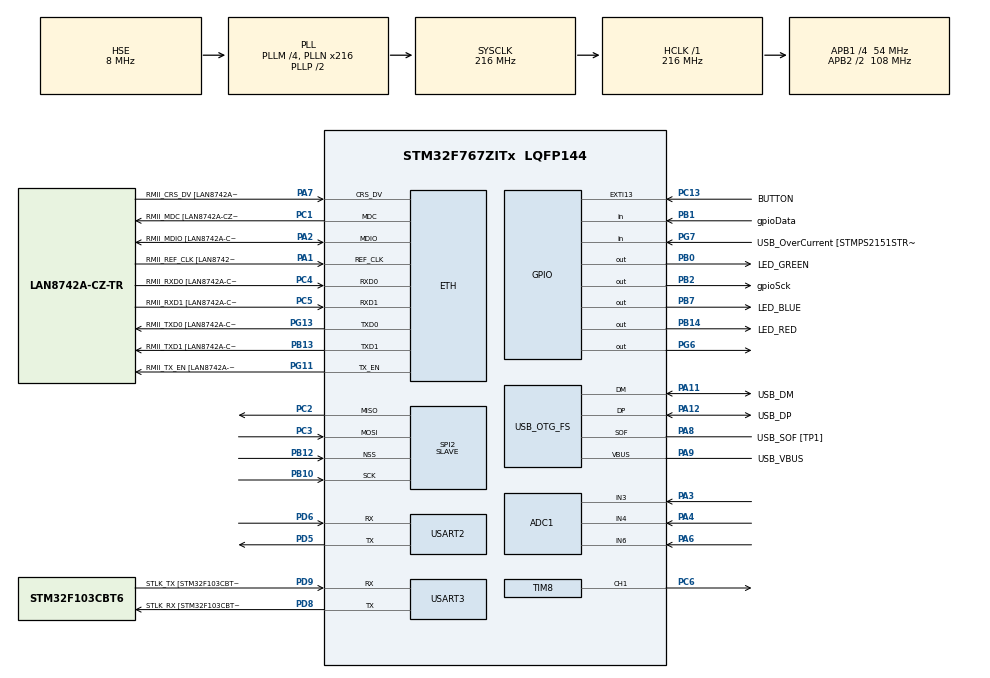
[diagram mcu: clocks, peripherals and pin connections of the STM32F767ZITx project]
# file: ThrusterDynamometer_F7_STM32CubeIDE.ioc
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ADC1.Channel-0\#ChannelRegularConversion=ADC_CHANNEL_3
ADC1.Channel-1\#ChannelRegularConversion=ADC_CHANNEL_4
ADC1.Channel-2\#ChannelRegularConversion=ADC_CHANNEL_6
ADC1.ClockPrescaler=ADC_CLOCK_SYNC_PCLK_DIV8
ADC1.DMAContinuousRequests=ENABLE
ADC1.ExternalTrigConv=ADC_EXTERNALTRIGCONV_T2_TRGO
ADC1.NbrOfConversion=3
ADC1.NbrOfConversionFlag=1
ADC1.Rank-0\#ChannelRegularConversion=1
ADC1.Rank-1\#ChannelRegularConversion=2
ADC1.Rank-2\#ChannelRegularConversion=3
ADC1.SamplingTime-0\#ChannelRegularConversion=ADC_SAMPLETIME_480CYCLES
ADC1.SamplingTime-1\#ChannelRegularConversion=ADC_SAMPLETIME_480CYCLES
ADC1.SamplingTime-2\#ChannelRegularConversion=ADC_SAMPLETIME_480CYCLES
ADC1.ScanConvMode=ADC_SCAN_ENABLE
ADC1.master=1
Dma.ADC1.1.Direction=DMA_PERIPH_TO_MEMORY
Dma.ADC1.1.FIFOMode=DMA_FIFOMODE_DISABLE
Dma.ADC1.1.Instance=DMA2_Stream0
Dma.ADC1.1.MemDataAlignment=DMA_MDATAALIGN_WORD
Dma.ADC1.1.MemInc=DMA_MINC_ENABLE
Dma.ADC1.1.Mode=DMA_CIRCULAR
Dma.ADC1.1.PeriphDataAlignment=DMA_PDATAALIGN_WORD
Dma.ADC1.1.PeriphInc=DMA_PINC_DISABLE
Dma.ADC1.1.Priority=DMA_PRIORITY_LOW
Dma.Request0=USART2_RX
Dma.Request1=ADC1
Dma.Request2=TIM8_CH1
Dma.Request3=SPI2_RX
Dma.Request4=SPI2_TX
Dma.SPI2_RX.3.Direction=DMA_PERIPH_TO_MEMORY
Dma.SPI2_RX.3.FIFOMode=DMA_FIFOMODE_ENABLE
Dma.SPI2_RX.3.FIFOThreshold=DMA_FIFO_THRESHOLD_FULL
Dma.SPI2_RX.3.Instance=DMA1_Stream1
Dma.SPI2_RX.3.MemBurst=DMA_MBURST_SINGLE
Dma.SPI2_RX.3.MemDataAlignment=DMA_MDATAALIGN_BYTE
Dma.SPI2_RX.3.MemInc=DMA_MINC_ENABLE
Dma.SPI2_RX.3.Mode=DMA_NORMAL
Dma.SPI2_RX.3.PeriphBurst=DMA_PBURST_SINGLE
Dma.SPI2_RX.3.PeriphDataAlignment=DMA_PDATAALIGN_BYTE
Dma.SPI2_RX.3.PeriphInc=DMA_PINC_DISABLE
Dma.SPI2_RX.3.Priority=DMA_PRIORITY_LOW
Dma.SPI2_TX.4.Direction=DMA_MEMORY_TO_PERIPH
Dma.SPI2_TX.4.FIFOMode=DMA_FIFOMODE_ENABLE
Dma.SPI2_TX.4.FIFOThreshold=DMA_FIFO_THRESHOLD_FULL
Dma.SPI2_TX.4.Instance=DMA1_Stream4
Dma.SPI2_TX.4.MemBurst=DMA_MBURST_SINGLE
Dma.SPI2_TX.4.MemDataAlignment=DMA_MDATAALIGN_BYTE
Dma.SPI2_TX.4.MemInc=DMA_MINC_ENABLE
Dma.SPI2_TX.4.Mode=DMA_NORMAL
Dma.SPI2_TX.4.PeriphBurst=DMA_PBURST_SINGLE
Dma.SPI2_TX.4.PeriphDataAlignment=DMA_PDATAALIGN_BYTE
Dma.SPI2_TX.4.PeriphInc=DMA_PINC_DISABLE
Dma.SPI2_TX.4.Priority=DMA_PRIORITY_LOW
Dma.TIM8_CH1.2.Direction=DMA_PERIPH_TO_MEMORY
Dma.TIM8_CH1.2.FIFOMode=DMA_FIFOMODE_DISABLE
Dma.TIM8_CH1.2.Instance=DMA2_Stream2
Dma.TIM8_CH1.2.MemDataAlignment=DMA_MDATAALIGN_HALFWORD
Dma.TIM8_CH1.2.MemInc=DMA_MINC_ENABLE
Dma.TIM8_CH1.2.Mode=DMA_CIRCULAR
Dma.TIM8_CH1.2.PeriphDataAlignment=DMA_PDATAALIGN_HALFWORD
Dma.TIM8_CH1.2.PeriphInc=DMA_PINC_DISABLE
Dma.TIM8_CH1.2.Priority=DMA_PRIORITY_LOW
Dma.USART2_RX.0.Direction=DMA_PERIPH_TO_MEMORY
Dma.USART2_RX.0.FIFOMode=DMA_FIFOMODE_DISABLE
Dma.USART2_RX.0.Instance=DMA1_Stream5
Dma.USART2_RX.0.MemDataAlignment=DMA_MDATAALIGN_BYTE
Dma.USART2_RX.0.MemInc=DMA_MINC_ENABLE
Dma.USART2_RX.0.Mode=DMA_NORMAL
Dma.USART2_RX.0.PeriphDataAlignment=DMA_PDATAALIGN_BYTE
Dma.USART2_RX.0.PeriphInc=DMA_PINC_DISABLE
Dma.USART2_RX.0.Priority=DMA_PRIORITY_LOW
ETH.MediaInterface=ETH_MEDIA_INTERFACE_RMII
ETH.PHY_Name=LAN8742A_PHY_ADDRESS
ETH.PHY_Value=0
ETH.PhyAddress=0
FREERTOS.Tasks01=defaultTask,0,128,StartDefaultTask,Default,NULL,Dynamic,NULL,NULL
FREERTOS.configTOTAL_HEAP_SIZE=50000
FREERTOS.configUSE_TIMERS=1
LWIP.IP_ADDRESS=169.254.000.055
LWIP.LWIP_DHCP=0
LWIP.NETMASK_ADDRESS=255.255.000.000
LWIP.Version=v2.1.2_Cube
Mcu.Family=STM32F7
Mcu.Name=STM32F767ZITx
Mcu.Package=LQFP144
NVIC.DMA1_Stream1_IRQn=true\:5\:0\:false\:false\:true\:true\:false\:true
NVIC.DMA1_Stream4_IRQn=true\:5\:0\:false\:false\:true\:true\:false\:true
NVIC.DMA1_Stream5_IRQn=true\:5\:0\:false\:false\:true\:true\:false\:true
NVIC.DMA2_Stream0_IRQn=true\:5\:0\:false\:false\:true\:true\:false\:true
NVIC.DMA2_Stream2_IRQn=true\:5\:0\:false\:false\:true\:true\:false\:true
NVIC.ETH_IRQn=true\:5\:0\:false\:false\:true\:true\:false\:true
NVIC.PriorityGroup=NVIC_PRIORITYGROUP_4
NVIC.SPI2_IRQn=true\:5\:0\:false\:false\:true\:true\:true\:true
NVIC.TIM1_BRK_TIM9_IRQn=true\:5\:0\:false\:false\:true\:true\:true\:true
NVIC.TIM1_TRG_COM_TIM11_IRQn=true\:5\:0\:false\:false\:true\:true\:true\:true
NVIC.TIM1_UP_TIM10_IRQn=true\:0\:0\:false\:false\:true\:false\:false\:true
NVIC.TIM2_IRQn=true\:5\:0\:false\:false\:true\:true\:true\:true
NVIC.TimeBase=TIM1_UP_TIM10_IRQn
NVIC.TimeBaseIP=TIM1
NVIC.USART2_IRQn=true\:5\:0\:false\:false\:true\:true\:true\:true
NVIC.USART3_IRQn=true\:5\:0\:false\:false\:true\:true\:true\:true
PA1.GPIO_Label=RMII_REF_CLK [LAN8742A-CZ-TR_REFCLK0]
PA1.Mode=RMII
PA1.Signal=ETH_REF_CLK
PA10.GPIO_Label=USB_ID
PA10.Signal=USB_OTG_FS_ID
PA11.GPIO_Label=USB_DM
PA11.Mode=Device_Only
PA11.Signal=USB_OTG_FS_DM
PA12.GPIO_Label=USB_DP
PA12.Mode=Device_Only
PA12.Signal=USB_OTG_FS_DP
PA13.GPIO_Label=TMS
PA13.Mode=Serial_Wire
PA13.Signal=SYS_JTMS-SWDIO
PA14.GPIO_Label=TCK
PA14.Mode=Serial_Wire
PA14.Signal=SYS_JTCK-SWCLK
PA2.GPIO_Label=RMII_MDIO [LAN8742A-CZ-TR_MDIO]
PA2.Mode=RMII
PA2.Signal=ETH_MDIO
PA3.Signal=ADCx_IN3
PA4.Signal=ADCx_IN4
PA6.Signal=ADCx_IN6
PA7.GPIO_Label=RMII_CRS_DV [LAN8742A-CZ-TR_CRS_DV]
PA7.Mode=RMII
PA7.Signal=ETH_CRS_DV
PA8.GPIO_Label=USB_SOF [TP1]
PA8.Mode=Activate_SOF_FS
PA8.Signal=USB_OTG_FS_SOF
PA9.GPIO_Label=USB_VBUS
PA9.Mode=Activate_VBUS
PA9.Signal=USB_OTG_FS_VBUS
PB0.GPIO_Label=LED_GREEN
PB0.Signal=GPIO_Output
PB1.GPIO_Label=gpioData
PB1.Signal=GPIO_Input
PB10.Mode=Full_Duplex_Slave
PB10.Signal=SPI2_SCK
PB12.Mode=NSS_Signal_Hard_Input
PB12.Signal=SPI2_NSS
PB13.GPIO_Label=RMII_TXD1 [LAN8742A-CZ-TR_TXD1]
PB13.Mode=RMII
PB13.Signal=ETH_TXD1
PB14.GPIO_Label=LED_RED
PB14.Signal=GPIO_Output
PB2.GPIO_Label=gpioSck
PB2.Signal=GPIO_Output
PB3.GPIO_Label=SWO
PB3.Signal=SYS_JTDO-SWO
PB7.GPIO_Label=LED_BLUE
PB7.Signal=GPIO_Output
PC1.GPIO_Label=RMII_MDC [LAN8742A-CZ-TR_MDC]
PC1.Mode=RMII
PC1.Signal=ETH_MDC
PC13.GPIO_Label=BUTTON
PC13.Signal=GPXTI13
PC14/OSC32_IN.Mode=LSE-External-Oscillator
PC14/OSC32_IN.Signal=RCC_OSC32_IN
PC15/OSC32_OUT.Mode=LSE-External-Oscillator
PC15/OSC32_OUT.Signal=RCC_OSC32_OUT
PC2.Mode=Full_Duplex_Slave
PC2.Signal=SPI2_MISO
PC3.Mode=Full_Duplex_Slave
PC3.Signal=SPI2_MOSI
PC4.GPIO_Label=RMII_RXD0 [LAN8742A-CZ-TR_RXD0]
PC4.Mode=RMII
PC4.Signal=ETH_RXD0
PC5.GPIO_Label=RMII_RXD1 [LAN8742A-CZ-TR_RXD1]
PC5.Mode=RMII
PC5.Signal=ETH_RXD1
PC6.Signal=S_TIM8_CH1
PD5.Mode=Asynchronous
PD5.Signal=USART2_TX
PD6.Mode=Asynchronous
PD6.Signal=USART2_RX
PD8.GPIO_Label=STLK_RX [STM32F103CBT6_PA3]
PD8.Mode=Asynchronous
PD8.Signal=USART3_TX
PD9.GPIO_Label=STLK_TX [STM32F103CBT6_PA2]
PD9.Mode=Asynchronous
PD9.Signal=USART3_RX
PG11.GPIO_Label=RMII_TX_EN [LAN8742A-CZ-TR_TXEN]
PG11.Mode=RMII
PG11.Signal=ETH_TX_EN
PG13.GPIO_Label=RMII_TXD0 [LAN8742A-CZ-TR_TXD0]
PG13.Mode=RMII
PG13.Signal=ETH_TXD0
PG6.Signal=GPIO_Output
PG7.GPIO_Label=USB_OverCurrent [STMPS2151STR_FAULT]
PG7.Signal=GPIO_Input
PH0/OSC_IN.GPIO_Label=MCO [STM32F103CBT6_PA8]
PH0/OSC_IN.Mode=HSE-External-Clock-Source
PH0/OSC_IN.Signal=RCC_OSC_IN
PH1/OSC_OUT.Mode=HSE-External-Clock-Source
PH1/OSC_OUT.Signal=RCC_OSC_OUT
ProjectManager.HeapSize=0x200
ProjectManager.StackSize=0x400
ProjectManager.TargetToolchain=STM32CubeIDE
RCC.48MHZClocksFreq_Value=24000000
RCC.AHBFreq_Value=216000000
RCC.APB1CLKDivider=RCC_HCLK_DIV4
RCC.APB1Freq_Value=54000000
RCC.APB1TimFreq_Value=108000000
RCC.APB2CLKDivider=RCC_HCLK_DIV2
RCC.APB2Freq_Value=108000000
RCC.APB2TimFreq_Value=216000000
RCC.CortexFreq_Value=216000000
RCC.HCLKFreq_Value=216000000
RCC.HSE_VALUE=8000000
RCC.HSI_VALUE=16000000
RCC.PLLM=4
RCC.PLLMUL=RCC_PLL_MUL9
RCC.PLLN=216
RCC.PLLQ=9
RCC.PRESCALERUSB=RCC_USBCLKSOURCE_PLL_DIV1_5
RCC.SYSCLKFreq_VALUE=216000000
RCC.SYSCLKSource=RCC_SYSCLKSOURCE_PLLCLK
RCC.SYSCLKSourceVirtual=RCC_SYSCLKSOURCE_PLLCLK
RCC.USBFreq_Value=48000000
RCC.VCOOutputFreq_Value=432000000
SH.ADCx_IN3.0=ADC1_IN3,IN3
SH.ADCx_IN4.0=ADC1_IN4,IN4
SH.ADCx_IN6.0=ADC1_IN6,IN6
SH.S_TIM8_CH1.0=TIM8_CH1,PWM Generation1 CH1
SPI2.DataSize=SPI_DATASIZE_8BIT
SPI2.Direction=SPI_DIRECTION_2LINES
SPI2.Mode=SPI_MODE_SLAVE
SPI2.VirtualNSS=VM_NSSHARD
SPI2.VirtualType=VM_SLAVE
TIM11.Period=999
TIM11.Prescaler=2159
TIM2.Period=999
TIM2.Prescaler=1079
TIM2.TIM_MasterOutputTrigger=TIM_TRGO_UPDATE
TIM8.Channel-PWM\ Generation1\ CH1=TIM_CHANNEL_1
TIM8.Period=10000
TIM8.Prescaler=440
TIM9.Period=9999
TIM9.Prescaler=2159
USART2.VirtualMode-Asynchronous=VM_ASYNC
USART3.VirtualMode-Asynchronous=VM_ASYNC
USB_OTG_FS.VirtualMode=Device_Only
VP_FREERTOS_VS_CMSIS_V1.Mode=CMSIS_V1
VP_LWIP_VS_Enabled.Mode=Enabled
VP_SYS_VS_tim1.Mode=TIM1
VP_TIM11_VS_ClockSourceINT.Mode=Enable_Timer
VP_TIM2_VS_ClockSourceINT.Mode=Internal
VP_TIM9_VS_ClockSourceINT.Mode=Internal
board=NUCLEO-F767ZI

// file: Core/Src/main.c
/* USER CODE BEGIN Header */
/**
  ******************************************************************************
  * @file           : main.c
  * @brief          : Main program body
  ******************************************************************************
  * @attention
  *
  * <h2><center>&copy; Copyright (c) 2020 STMicroelectronics.
  * All rights reserved.</center></h2>
  *
  * This software component is licensed by ST under Ultimate Liberty license
  * SLA0044, the "License"; You may not use this file except in compliance with
  * the License. You may obtain a copy of the License at:
  *                             www.st.com/SLA0044
  *
  ******************************************************************************
  */
/* USER CODE END Header */

#include "main.h"
#include "cmsis_os.h"
#include "lwip.h"
#include "thruster_control_module.h"

ADC_HandleTypeDef hadc1;
DMA_HandleTypeDef hdma_adc1;

SPI_HandleTypeDef hspi2;
DMA_HandleTypeDef hdma_spi2_rx;
DMA_HandleTypeDef hdma_spi2_tx;

TIM_HandleTypeDef htim2;
TIM_HandleTypeDef htim8;
TIM_HandleTypeDef htim9;
TIM_HandleTypeDef htim11;
DMA_HandleTypeDef hdma_tim8_ch1;

UART_HandleTypeDef huart2;
UART_HandleTypeDef huart3;
DMA_HandleTypeDef hdma_usart2_rx;

PCD_HandleTypeDef hpcd_USB_OTG_FS;

osThreadId defaultTaskHandle;

void SystemClock_Config(void);
static void MX_GPIO_Init(void);
static void MX_DMA_Init(void);
static void MX_USART3_UART_Init(void);
static void MX_USB_OTG_FS_PCD_Init(void);
static void MX_ADC1_Init(void);
static void MX_TIM2_Init(void);
static void MX_TIM8_Init(void);
static void MX_TIM9_Init(void);
static void MX_TIM11_Init(void);
static void MX_USART2_UART_Init(void);
static void MX_SPI2_Init(void);
void StartDefaultTask(void const * argument);

/* USER CODE BEGIN 0 */

#define UART_DATA_LEN	100
uint8_t data[UART_DATA_LEN];

/* USER CODE END 0 */

int main(void)
{

  /* MCU Configuration--------------------------------------------------------*/

  /* Reset of all peripherals, Initializes the Flash interface and the Systick. */
  HAL_Init();

  /* Configure the system clock */
  SystemClock_Config();

  /* Initialize all configured peripherals */
  MX_GPIO_Init();
  MX_DMA_Init();
  MX_USART3_UART_Init();
  MX_USB_OTG_FS_PCD_Init();
  MX_ADC1_Init();
  MX_TIM2_Init();
  MX_TIM8_Init();
  MX_TIM9_Init();
  MX_TIM11_Init();
  MX_USART2_UART_Init();
  MX_SPI2_Init();

  /* Create the thread(s) */
  /* definition and creation of defaultTask */
//  osThreadDef(defaultTask, StartDefaultTask, osPriorityNormal, 0, 128);
//  defaultTaskHandle = osThreadCreate(osThread(defaultTask), NULL);

  ThrusterControlModule_InitSystem();

  /* Start scheduler */
  osKernelStart();

  /* We should never get here as control is now taken by the scheduler */
  /* Infinite loop */
  while (1)
  {

  }
}

void SystemClock_Config(void)
{
  RCC_OscInitTypeDef RCC_OscInitStruct = {0};
  RCC_ClkInitTypeDef RCC_ClkInitStruct = {0};
  RCC_PeriphCLKInitTypeDef PeriphClkInitStruct = {0};

  /** Configure LSE Drive Capability
  */
  HAL_PWR_EnableBkUpAccess();
  /** Configure the main internal regulator output voltage
  */
  __HAL_RCC_PWR_CLK_ENABLE();
  __HAL_PWR_VOLTAGESCALING_CONFIG(PWR_REGULATOR_VOLTAGE_SCALE1);
  /** Initializes the CPU, AHB and APB busses clocks
  */
  RCC_OscInitStruct.OscillatorType = RCC_OSCILLATORTYPE_HSE;
  RCC_OscInitStruct.HSEState = RCC_HSE_BYPASS;
  RCC_OscInitStruct.PLL.PLLState = RCC_PLL_ON;
  RCC_OscInitStruct.PLL.PLLSource = RCC_PLLSOURCE_HSE;
  RCC_OscInitStruct.PLL.PLLM = 4;
  RCC_OscInitStruct.PLL.PLLN = 216;
  RCC_OscInitStruct.PLL.PLLP = RCC_PLLP_DIV2;
  RCC_OscInitStruct.PLL.PLLQ = 9;
  if (HAL_RCC_OscConfig(&RCC_OscInitStruct) != HAL_OK)
  {
    Error_Handler();
  }
  /** Activate the Over-Drive mode
  */
  if (HAL_PWREx_EnableOverDrive() != HAL_OK)
  {
    Error_Handler();
  }
  /** Initializes the CPU, AHB and APB busses clocks
  */
  RCC_ClkInitStruct.ClockType = RCC_CLOCKTYPE_HCLK|RCC_CLOCKTYPE_SYSCLK
                              |RCC_CLOCKTYPE_PCLK1|RCC_CLOCKTYPE_PCLK2;
  RCC_ClkInitStruct.SYSCLKSource = RCC_SYSCLKSOURCE_PLLCLK;
  RCC_ClkInitStruct.AHBCLKDivider = RCC_SYSCLK_DIV1;
  RCC_ClkInitStruct.APB1CLKDivider = RCC_HCLK_DIV4;
  RCC_ClkInitStruct.APB2CLKDivider = RCC_HCLK_DIV2;

  if (HAL_RCC_ClockConfig(&RCC_ClkInitStruct, FLASH_LATENCY_7) != HAL_OK)
  {
    Error_Handler();
  }
  PeriphClkInitStruct.PeriphClockSelection = RCC_PERIPHCLK_USART2|RCC_PERIPHCLK_USART3
                              |RCC_PERIPHCLK_CLK48;
  PeriphClkInitStruct.Usart2ClockSelection = RCC_USART2CLKSOURCE_PCLK1;
  PeriphClkInitStruct.Usart3ClockSelection = RCC_USART3CLKSOURCE_PCLK1;
  PeriphClkInitStruct.Clk48ClockSelection = RCC_CLK48SOURCE_PLL;
  if (HAL_RCCEx_PeriphCLKConfig(&PeriphClkInitStruct) != HAL_OK)
  {
    Error_Handler();
  }
}

static void MX_ADC1_Init(void)
{

  ADC_ChannelConfTypeDef sConfig = {0};

  /** Configure the global features of the ADC (Clock, Resolution, Data Alignment and number of conversion)
  */
  hadc1.Instance = ADC1;
  hadc1.Init.ClockPrescaler = ADC_CLOCK_SYNC_PCLK_DIV8;
  hadc1.Init.Resolution = ADC_RESOLUTION_12B;
  hadc1.Init.ScanConvMode = ADC_SCAN_ENABLE;
  hadc1.Init.ContinuousConvMode = DISABLE;
  hadc1.Init.DiscontinuousConvMode = DISABLE;
  hadc1.Init.ExternalTrigConvEdge = ADC_EXTERNALTRIGCONVEDGE_RISING;
  hadc1.Init.ExternalTrigConv = ADC_EXTERNALTRIGCONV_T2_TRGO;
  hadc1.Init.DataAlign = ADC_DATAALIGN_RIGHT;
  hadc1.Init.NbrOfConversion = 3;
  hadc1.Init.DMAContinuousRequests = ENABLE;
  hadc1.Init.EOCSelection = ADC_EOC_SINGLE_CONV;
  if (HAL_ADC_Init(&hadc1) != HAL_OK)
  {
    Error_Handler();
  }
  /** Configure for the selected ADC regular channel its corresponding rank in the sequencer and its sample time.
  */
  sConfig.Channel = ADC_CHANNEL_3;
  sConfig.Rank = ADC_REGULAR_RANK_1;
  sConfig.SamplingTime = ADC_SAMPLETIME_480CYCLES;
  if (HAL_ADC_ConfigChannel(&hadc1, &sConfig) != HAL_OK)
  {
    Error_Handler();
  }
  /** Configure for the selected ADC regular channel its corresponding rank in the sequencer and its sample time.
  */
  sConfig.Channel = ADC_CHANNEL_4;
  sConfig.Rank = ADC_REGULAR_RANK_2;
  if (HAL_ADC_ConfigChannel(&hadc1, &sConfig) != HAL_OK)
  {
    Error_Handler();
  }
  /** Configure for the selected ADC regular channel its corresponding rank in the sequencer and its sample time.
  */
  sConfig.Channel = ADC_CHANNEL_6;
  sConfig.Rank = ADC_REGULAR_RANK_3;
  if (HAL_ADC_ConfigChannel(&hadc1, &sConfig) != HAL_OK)
  {
    Error_Handler();
  }

}

static void MX_SPI2_Init(void)
{

  /* SPI2 parameter configuration*/
  hspi2.Instance = SPI2;
  hspi2.Init.Mode = SPI_MODE_SLAVE;
  hspi2.Init.Direction = SPI_DIRECTION_2LINES;
  hspi2.Init.DataSize = SPI_DATASIZE_8BIT;
  hspi2.Init.CLKPolarity = SPI_POLARITY_LOW;
  hspi2.Init.CLKPhase = SPI_PHASE_1EDGE;
  hspi2.Init.NSS = SPI_NSS_HARD_INPUT;
  hspi2.Init.FirstBit = SPI_FIRSTBIT_MSB;
  hspi2.Init.TIMode = SPI_TIMODE_DISABLE;
  hspi2.Init.CRCCalculation = SPI_CRCCALCULATION_DISABLE;
  hspi2.Init.CRCPolynomial = 7;
  hspi2.Init.CRCLength = SPI_CRC_LENGTH_DATASIZE;
  hspi2.Init.NSSPMode = SPI_NSS_PULSE_DISABLE;
  if (HAL_SPI_Init(&hspi2) != HAL_OK)
  {
    Error_Handler();
  }

}

static void MX_TIM2_Init(void)
{

  TIM_ClockConfigTypeDef sClockSourceConfig = {0};
  TIM_MasterConfigTypeDef sMasterConfig = {0};

  htim2.Instance = TIM2;
  htim2.Init.Prescaler = 1079;
  htim2.Init.CounterMode = TIM_COUNTERMODE_UP;
  htim2.Init.Period = 999;
  htim2.Init.ClockDivision = TIM_CLOCKDIVISION_DIV1;
  htim2.Init.AutoReloadPreload = TIM_AUTORELOAD_PRELOAD_DISABLE;
  if (HAL_TIM_Base_Init(&htim2) != HAL_OK)
  {
    Error_Handler();
  }
  sClockSourceConfig.ClockSource = TIM_CLOCKSOURCE_INTERNAL;
  if (HAL_TIM_ConfigClockSource(&htim2, &sClockSourceConfig) != HAL_OK)
  {
    Error_Handler();
  }
  sMasterConfig.MasterOutputTrigger = TIM_TRGO_UPDATE;
  sMasterConfig.MasterSlaveMode = TIM_MASTERSLAVEMODE_DISABLE;
  if (HAL_TIMEx_MasterConfigSynchronization(&htim2, &sMasterConfig) != HAL_OK)
  {
    Error_Handler();
  }

}

static void MX_TIM8_Init(void)
{

  TIM_MasterConfigTypeDef sMasterConfig = {0};
  TIM_OC_InitTypeDef sConfigOC = {0};
  TIM_BreakDeadTimeConfigTypeDef sBreakDeadTimeConfig = {0};

  htim8.Instance = TIM8;
  htim8.Init.Prescaler = 440;
  htim8.Init.CounterMode = TIM_COUNTERMODE_UP;
  htim8.Init.Period = 10000;
  htim8.Init.ClockDivision = TIM_CLOCKDIVISION_DIV1;
  htim8.Init.RepetitionCounter = 0;
  htim8.Init.AutoReloadPreload = TIM_AUTORELOAD_PRELOAD_DISABLE;
  if (HAL_TIM_PWM_Init(&htim8) != HAL_OK)
  {
    Error_Handler();
  }
  sMasterConfig.MasterOutputTrigger = TIM_TRGO_RESET;
  sMasterConfig.MasterOutputTrigger2 = TIM_TRGO2_RESET;
  sMasterConfig.MasterSlaveMode = TIM_MASTERSLAVEMODE_DISABLE;
  if (HAL_TIMEx_MasterConfigSynchronization(&htim8, &sMasterConfig) != HAL_OK)
  {
    Error_Handler();
  }
  sConfigOC.OCMode = TIM_OCMODE_PWM1;
  sConfigOC.Pulse = 0;
  sConfigOC.OCPolarity = TIM_OCPOLARITY_HIGH;
  sConfigOC.OCNPolarity = TIM_OCNPOLARITY_HIGH;
  sConfigOC.OCFastMode = TIM_OCFAST_DISABLE;
  sConfigOC.OCIdleState = TIM_OCIDLESTATE_RESET;
  sConfigOC.OCNIdleState = TIM_OCNIDLESTATE_RESET;
  if (HAL_TIM_PWM_ConfigChannel(&htim8, &sConfigOC, TIM_CHANNEL_1) != HAL_OK)
  {
    Error_Handler();
  }
  sBreakDeadTimeConfig.OffStateRunMode = TIM_OSSR_DISABLE;
  sBreakDeadTimeConfig.OffStateIDLEMode = TIM_OSSI_DISABLE;
  sBreakDeadTimeConfig.LockLevel = TIM_LOCKLEVEL_OFF;
  sBreakDeadTimeConfig.DeadTime = 0;
  sBreakDeadTimeConfig.BreakState = TIM_BREAK_DISABLE;
  sBreakDeadTimeConfig.BreakPolarity = TIM_BREAKPOLARITY_HIGH;
  sBreakDeadTimeConfig.BreakFilter = 0;
  sBreakDeadTimeConfig.Break2State = TIM_BREAK2_DISABLE;
  sBreakDeadTimeConfig.Break2Polarity = TIM_BREAK2POLARITY_HIGH;
  sBreakDeadTimeConfig.Break2Filter = 0;
  sBreakDeadTimeConfig.AutomaticOutput = TIM_AUTOMATICOUTPUT_DISABLE;
  if (HAL_TIMEx_ConfigBreakDeadTime(&htim8, &sBreakDeadTimeConfig) != HAL_OK)
  {
    Error_Handler();
  }
  HAL_TIM_MspPostInit(&htim8);

}

static void MX_TIM9_Init(void)
{

  TIM_ClockConfigTypeDef sClockSourceConfig = {0};

  htim9.Instance = TIM9;
  htim9.Init.Prescaler = 2159;
  htim9.Init.CounterMode = TIM_COUNTERMODE_UP;
  htim9.Init.Period = 9999;
  htim9.Init.ClockDivision = TIM_CLOCKDIVISION_DIV1;
  htim9.Init.AutoReloadPreload = TIM_AUTORELOAD_PRELOAD_DISABLE;
  if (HAL_TIM_Base_Init(&htim9) != HAL_OK)
  {
    Error_Handler();
  }
  sClockSourceConfig.ClockSource = TIM_CLOCKSOURCE_INTERNAL;
  if (HAL_TIM_ConfigClockSource(&htim9, &sClockSourceConfig) != HAL_OK)
  {
    Error_Handler();
  }

}

static void MX_TIM11_Init(void)
{

  htim11.Instance = TIM11;
  htim11.Init.Prescaler = 2159;
  htim11.Init.CounterMode = TIM_COUNTERMODE_UP;
  htim11.Init.Period = 999;
  htim11.Init.ClockDivision = TIM_CLOCKDIVISION_DIV1;
  htim11.Init.AutoReloadPreload = TIM_AUTORELOAD_PRELOAD_DISABLE;
  if (HAL_TIM_Base_Init(&htim11) != HAL_OK)
  {
    Error_Handler();
  }

}

static void MX_USART2_UART_Init(void)
{

  huart2.Instance = USART2;
  huart2.Init.BaudRate = 115200;
  huart2.Init.WordLength = UART_WORDLENGTH_8B;
  huart2.Init.StopBits = UART_STOPBITS_1;
  huart2.Init.Parity = UART_PARITY_NONE;
  huart2.Init.Mode = UART_MODE_TX_RX;
  huart2.Init.HwFlowCtl = UART_HWCONTROL_NONE;
  huart2.Init.OverSampling = UART_OVERSAMPLING_16;
  huart2.Init.OneBitSampling = UART_ONE_BIT_SAMPLE_DISABLE;
  huart2.AdvancedInit.AdvFeatureInit = UART_ADVFEATURE_NO_INIT;
  if (HAL_UART_Init(&huart2) != HAL_OK)
  {
    Error_Handler();
  }

}

static void MX_USART3_UART_Init(void)
{

  /* USER CODE BEGIN USART3_Init 0 */

  __HAL_UART_ENABLE_IT(&huart3, UART_IT_IDLE); //enable idle line interrupt for RX

  /* USER CODE END USART3_Init 0 */

  huart3.Instance = USART3;
  huart3.Init.BaudRate = 115200;
  huart3.Init.WordLength = UART_WORDLENGTH_8B;
  huart3.Init.StopBits = UART_STOPBITS_1;
  huart3.Init.Parity = UART_PARITY_NONE;
  huart3.Init.Mode = UART_MODE_TX_RX;
  huart3.Init.HwFlowCtl = UART_HWCONTROL_NONE;
  huart3.Init.OverSampling = UART_OVERSAMPLING_16;
  huart3.Init.OneBitSampling = UART_ONE_BIT_SAMPLE_DISABLE;
  huart3.AdvancedInit.AdvFeatureInit = UART_ADVFEATURE_NO_INIT;
  if (HAL_UART_Init(&huart3) != HAL_OK)
  {
    Error_Handler();
  }

}

static void MX_USB_OTG_FS_PCD_Init(void)
{

  hpcd_USB_OTG_FS.Instance = USB_OTG_FS;
  hpcd_USB_OTG_FS.Init.dev_endpoints = 6;
  hpcd_USB_OTG_FS.Init.speed = PCD_SPEED_FULL;
  hpcd_USB_OTG_FS.Init.dma_enable = DISABLE;
  hpcd_USB_OTG_FS.Init.phy_itface = PCD_PHY_EMBEDDED;
  hpcd_USB_OTG_FS.Init.Sof_enable = ENABLE;
  hpcd_USB_OTG_FS.Init.low_power_enable = DISABLE;
  hpcd_USB_OTG_FS.Init.lpm_enable = DISABLE;
  hpcd_USB_OTG_FS.Init.vbus_sensing_enable = ENABLE;
  hpcd_USB_OTG_FS.Init.use_dedicated_ep1 = DISABLE;
  if (HAL_PCD_Init(&hpcd_USB_OTG_FS) != HAL_OK)
  {
    Error_Handler();
  }

}

static void MX_DMA_Init(void)
{

  /* DMA controller clock enable */
  __HAL_RCC_DMA1_CLK_ENABLE();
  __HAL_RCC_DMA2_CLK_ENABLE();

  /* DMA interrupt init */
  /* DMA1_Stream1_IRQn interrupt configuration */
  HAL_NVIC_SetPriority(DMA1_Stream1_IRQn, 5, 0);
  HAL_NVIC_EnableIRQ(DMA1_Stream1_IRQn);
  /* DMA1_Stream4_IRQn interrupt configuration */
  HAL_NVIC_SetPriority(DMA1_Stream4_IRQn, 5, 0);
  HAL_NVIC_EnableIRQ(DMA1_Stream4_IRQn);
  /* DMA1_Stream5_IRQn interrupt configuration */
  HAL_NVIC_SetPriority(DMA1_Stream5_IRQn, 5, 0);
  HAL_NVIC_EnableIRQ(DMA1_Stream5_IRQn);
  /* DMA2_Stream0_IRQn interrupt configuration */
  HAL_NVIC_SetPriority(DMA2_Stream0_IRQn, 5, 0);
  HAL_NVIC_EnableIRQ(DMA2_Stream0_IRQn);
  /* DMA2_Stream2_IRQn interrupt configuration */
  HAL_NVIC_SetPriority(DMA2_Stream2_IRQn, 5, 0);
  HAL_NVIC_EnableIRQ(DMA2_Stream2_IRQn);

}

static void MX_GPIO_Init(void)
{
  GPIO_InitTypeDef GPIO_InitStruct = {0};

  /* GPIO Ports Clock Enable */
  __HAL_RCC_GPIOC_CLK_ENABLE();
  __HAL_RCC_GPIOH_CLK_ENABLE();
  __HAL_RCC_GPIOA_CLK_ENABLE();
  __HAL_RCC_GPIOB_CLK_ENABLE();
  __HAL_RCC_GPIOD_CLK_ENABLE();
  __HAL_RCC_GPIOG_CLK_ENABLE();

  /*Configure GPIO pin Output Level */
  HAL_GPIO_WritePin(GPIOB, LED_GREEN_Pin|gpioSck_Pin|LED_RED_Pin|LED_BLUE_Pin, GPIO_PIN_RESET);

  /*Configure GPIO pin Output Level */
  HAL_GPIO_WritePin(GPIOG, GPIO_PIN_6, GPIO_PIN_RESET);

  /*Configure GPIO pin : BUTTON_Pin */
  GPIO_InitStruct.Pin = BUTTON_Pin;
  GPIO_InitStruct.Mode = GPIO_MODE_IT_RISING;
  GPIO_InitStruct.Pull = GPIO_NOPULL;
  HAL_GPIO_Init(BUTTON_GPIO_Port, &GPIO_InitStruct);

  /*Configure GPIO pins : LED_GREEN_Pin gpioSck_Pin LED_RED_Pin LED_BLUE_Pin */
  GPIO_InitStruct.Pin = LED_GREEN_Pin|gpioSck_Pin|LED_RED_Pin|LED_BLUE_Pin;
  GPIO_InitStruct.Mode = GPIO_MODE_OUTPUT_PP;
  GPIO_InitStruct.Pull = GPIO_NOPULL;
  GPIO_InitStruct.Speed = GPIO_SPEED_FREQ_LOW;
  HAL_GPIO_Init(GPIOB, &GPIO_InitStruct);

  /*Configure GPIO pin : gpioData_Pin */
  GPIO_InitStruct.Pin = gpioData_Pin;
  GPIO_InitStruct.Mode = GPIO_MODE_INPUT;
  GPIO_InitStruct.Pull = GPIO_NOPULL;
  HAL_GPIO_Init(gpioData_GPIO_Port, &GPIO_InitStruct);

  /*Configure GPIO pin : PG6 */
  GPIO_InitStruct.Pin = GPIO_PIN_6;
  GPIO_InitStruct.Mode = GPIO_MODE_OUTPUT_PP;
  GPIO_InitStruct.Pull = GPIO_NOPULL;
  GPIO_InitStruct.Speed = GPIO_SPEED_FREQ_LOW;
  HAL_GPIO_Init(GPIOG, &GPIO_InitStruct);

  /*Configure GPIO pin : USB_OverCurrent_Pin */
  GPIO_InitStruct.Pin = USB_OverCurrent_Pin;
  GPIO_InitStruct.Mode = GPIO_MODE_INPUT;
  GPIO_InitStruct.Pull = GPIO_NOPULL;
  HAL_GPIO_Init(USB_OverCurrent_GPIO_Port, &GPIO_InitStruct);

}

void StartDefaultTask(void const * argument)
{
  /* init code for LWIP */
  MX_LWIP_Init();
  for(;;)
  {
    osDelay(1);
  }
}

 /**
  * @brief  Period elapsed callback in non blocking mode
  * @note   This function is called  when TIM1 interrupt took place, inside
  * HAL_TIM_IRQHandler(). It makes a direct call to HAL_IncTick() to increment
  * a global variable "uwTick" used as application time base.
  * @param  htim : TIM handle
  * @retval None
  */
void HAL_TIM_PeriodElapsedCallback(TIM_HandleTypeDef *htim)
{
  if (htim->Instance == TIM1) {
    HAL_IncTick();
  }
}

void Error_Handler(void)
{
}

/************************ (C) COPYRIGHT STMicroelectronics *****END OF FILE****/
